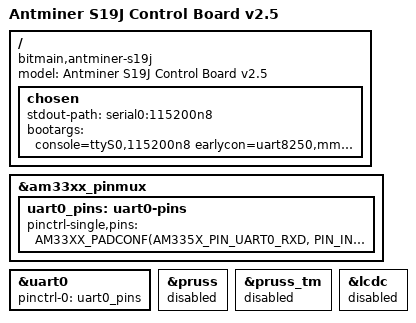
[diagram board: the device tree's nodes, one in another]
/*
 * Device Tree Source for Antminer S19J Control Board v2.5 (TI AM335x)
 * Target Kernel: Linux 6.6+
 */

/dts-v1/;

#include "am335x-boneblack.dts"

/ {
	model = "Antminer S19J Control Board v2.5";
	compatible = "bitmain,antminer-s19j", "ti,am335x-boneblack", "ti,am33xx";

	chosen {
		stdout-path = "serial0:115200n8";
		bootargs = "console=ttyS0,115200n8 earlycon=uart8250,mmio32,0x44e09000 root=/dev/mmcblk0p2 rw rootwait";
	};
};

&am33xx_pinmux {
	uart0_pins: uart0-pins {
		pinctrl-single,pins = <
			AM33XX_PADCONF(AM335X_PIN_UART0_RXD, PIN_INPUT_PULLUP, MUX_MODE0)
			AM33XX_PADCONF(AM335X_PIN_UART0_TXD, PIN_OUTPUT_PULLDOWN, MUX_MODE0)
		>;
	};
};

&uart0 {
	pinctrl-names = "default";
	pinctrl-0 = <&uart0_pins>;
	status = "okay";
	/* 
	 * CRITICAL: Disable DMA for UART0.
	 * 8250_omap with DMA causes RX keystrokes from PuTTY to be trapped in eDMA buffers
	 * without triggering RX interrupts for single character terminal inputs.
	 * Removing dmas forces PIO mode (interrupt-driven), making PuTTY typing responsive!
	 */
	/delete-property/ dmas;
	/delete-property/ dma-names;
};

/* 
 * CRITICAL FIX: Disable PRU-ICSS Subsystem & Interconnect Target Module
 * Physical address 0x4a326000 (target-module@30000) is unclocked on Antminer hardware.
 * Disabling pruss & pruss_tm prevents ti-sysc from probing 0x4a326000 and causing External Abort (0x1008).
 */
&pruss {
	status = "disabled";
};

&pruss_tm {
	status = "disabled";
};

/* Disable LCD Controller */
&lcdc {
	status = "disabled";
};
